# PIC32MZ2048EFM144 register map
Registers are 32-bit, access not given, reset 0x0 unless marked. A register's access mark holds for its fields unless they carry their own. Offsets are from the block's base; [hi:lo] are bit positions; {n}, {i} and the like mark numbered series; 'fields as' and 'values as' point back to an identical list.

## CAN1 — CAN1 peripheral
Base 0xBF880000
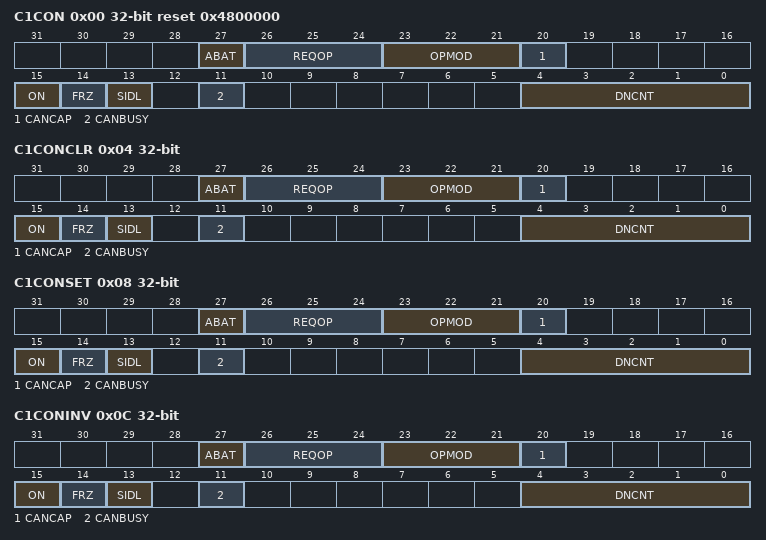
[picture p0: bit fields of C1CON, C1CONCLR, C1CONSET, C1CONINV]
0x00 C1CON reset 0x4800000
  [27] ABAT, [26:24] REQOP, [23:21] OPMOD, [20] CANCAP, [15] ON, [14] FRZ, [13] SIDL, [11] CANBUSY, [4:0] DNCNT
0x04 C1CONCLR
  fields as C1CON
0x08 C1CONSET
  fields as C1CON
0x0C C1CONINV
  fields as C1CON
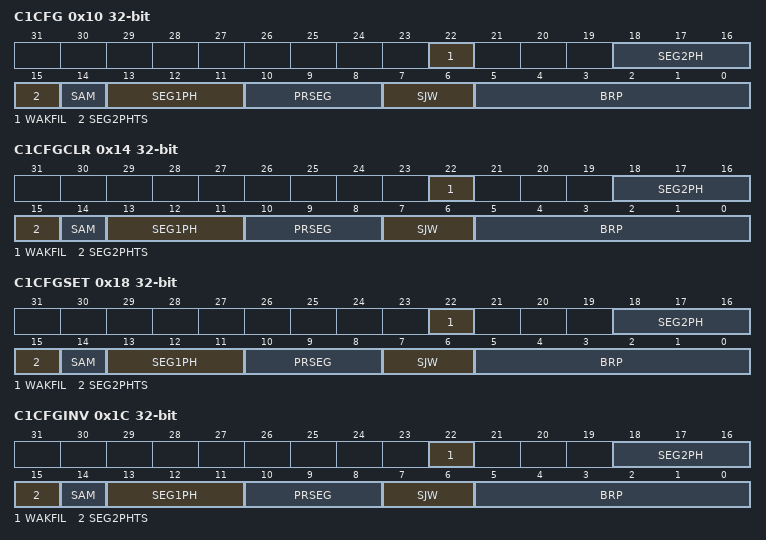
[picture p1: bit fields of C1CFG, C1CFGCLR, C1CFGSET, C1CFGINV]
0x10 C1CFG
  [22] WAKFIL, [18:16] SEG2PH, [15] SEG2PHTS, [14] SAM, [13:11] SEG1PH, [10:8] PRSEG, [7:6] SJW, [5:0] BRP
0x14 C1CFGCLR
  fields as C1CFG
0x18 C1CFGSET
  fields as C1CFG
0x1C C1CFGINV
  fields as C1CFG
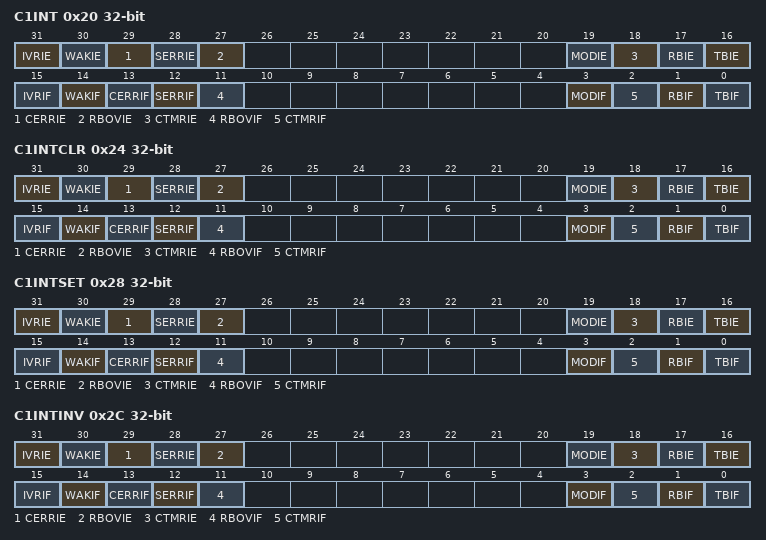
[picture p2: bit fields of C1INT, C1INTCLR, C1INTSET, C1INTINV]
0x20 C1INT
  [31] IVRIE, [30] WAKIE, [29] CERRIE, [28] SERRIE, [27] RBOVIE, [19] MODIE, [18] CTMRIE, [17] RBIE, [16] TBIE, [15] IVRIF, [14] WAKIF, [13] CERRIF, [12] SERRIF, [11] RBOVIF, [3] MODIF, [2] CTMRIF, [1] RBIF, [0] TBIF
0x24 C1INTCLR
  fields as C1INT
0x28 C1INTSET
  fields as C1INT
0x2C C1INTINV
  fields as C1INT
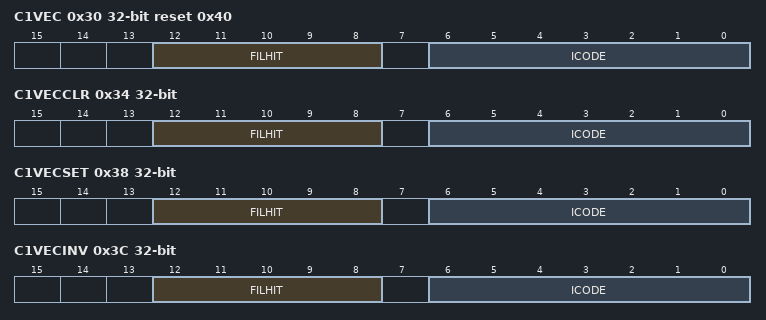
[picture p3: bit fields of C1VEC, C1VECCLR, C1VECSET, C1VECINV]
0x30 C1VEC reset 0x40
  [12:8] FILHIT, [6:0] ICODE
0x34 C1VECCLR
  [12:8] FILHIT, [6:0] ICODE
0x38 C1VECSET
  [12:8] FILHIT, [6:0] ICODE
0x3C C1VECINV
  [12:8] FILHIT, [6:0] ICODE
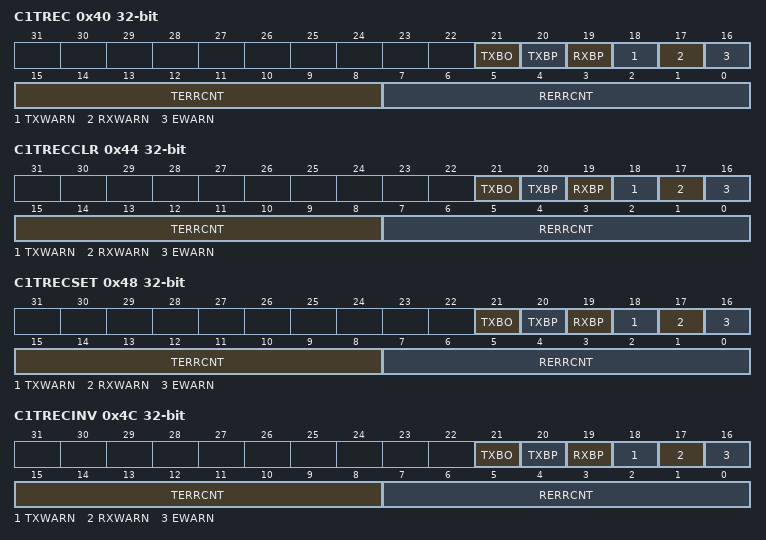
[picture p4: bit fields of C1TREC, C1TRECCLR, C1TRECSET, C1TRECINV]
0x40 C1TREC
  [21] TXBO, [20] TXBP, [19] RXBP, [18] TXWARN, [17] RXWARN, [16] EWARN, [15:8] TERRCNT, [7:0] RERRCNT
0x44 C1TRECCLR
  fields as C1TREC
0x48 C1TRECSET
  fields as C1TREC
0x4C C1TRECINV
  fields as C1TREC
0x50 C1FSTAT
  [31:0] FIFOIP
0x54 C1FSTATCLR
  [31:0] FIFOIP
0x58 C1FSTATSET
  [31:0] FIFOIP
0x5C C1FSTATINV
  [31:0] FIFOIP
0x60 C1RXOVF
  [31:0] RXOVF
0x64 C1RXOVFCLR
  [31:0] RXOVF
0x68 C1RXOVFSET
  [31:0] RXOVF
0x6C C1RXOVFINV
  [31:0] RXOVF
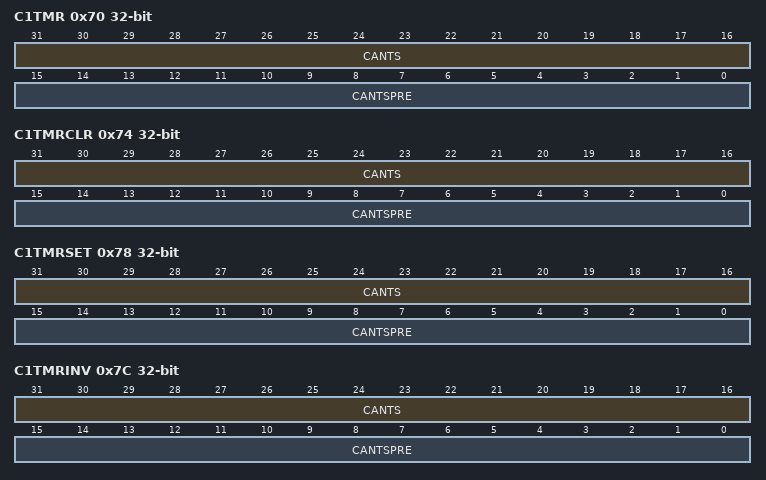
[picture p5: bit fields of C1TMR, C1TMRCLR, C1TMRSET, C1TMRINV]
0x70 C1TMR
  [31:16] CANTS, [15:0] CANTSPRE
0x74 C1TMRCLR
  [31:16] CANTS, [15:0] CANTSPRE
0x78 C1TMRSET
  [31:16] CANTS, [15:0] CANTSPRE
0x7C C1TMRINV
  [31:16] CANTS, [15:0] CANTSPRE
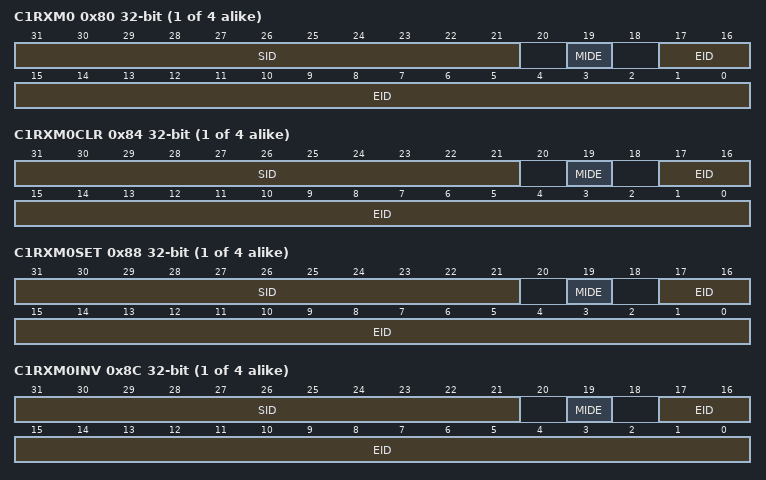
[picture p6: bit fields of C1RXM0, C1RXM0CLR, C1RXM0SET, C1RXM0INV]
{0x80+0x10*i} C1RXM{i} (i=0..3)
  [31:21] SID, [19] MIDE, [17:0] EID
{0x84+0x10*i} C1RXM{i}CLR (i=0..3)
  [31:21] SID, [19] MIDE, [17:0] EID
{0x88+0x10*i} C1RXM{i}SET (i=0..3)
  [31:21] SID, [19] MIDE, [17:0] EID
{0x8C+0x10*i} C1RXM{i}INV (i=0..3)
  [31:21] SID, [19] MIDE, [17:0] EID
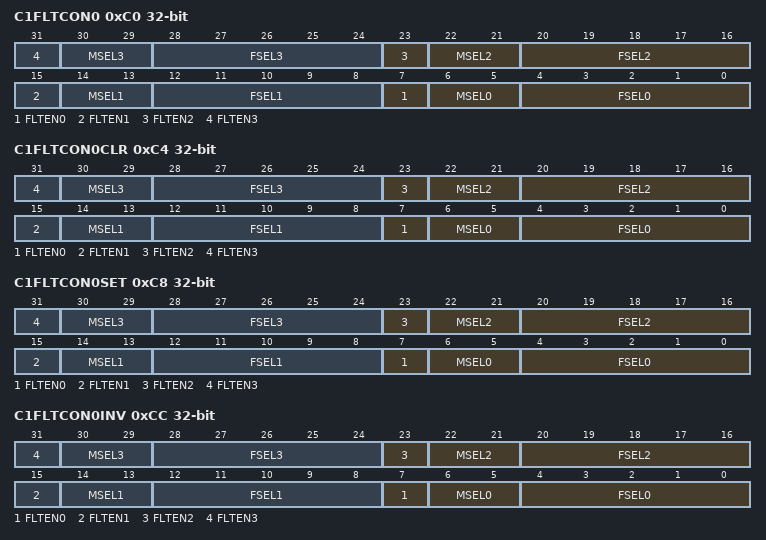
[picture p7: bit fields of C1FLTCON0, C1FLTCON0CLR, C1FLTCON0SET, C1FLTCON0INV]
0xC0 C1FLTCON0
  [8n+7] FLTEN{n} (n=0..3), [8n+6:8n+5] MSEL{n} (n=0..3), [8n+4:8n] FSEL{n} (n=0..3)
0xC4 C1FLTCON0CLR
  fields as C1FLTCON0
0xC8 C1FLTCON0SET
  fields as C1FLTCON0
0xCC C1FLTCON0INV
  fields as C1FLTCON0
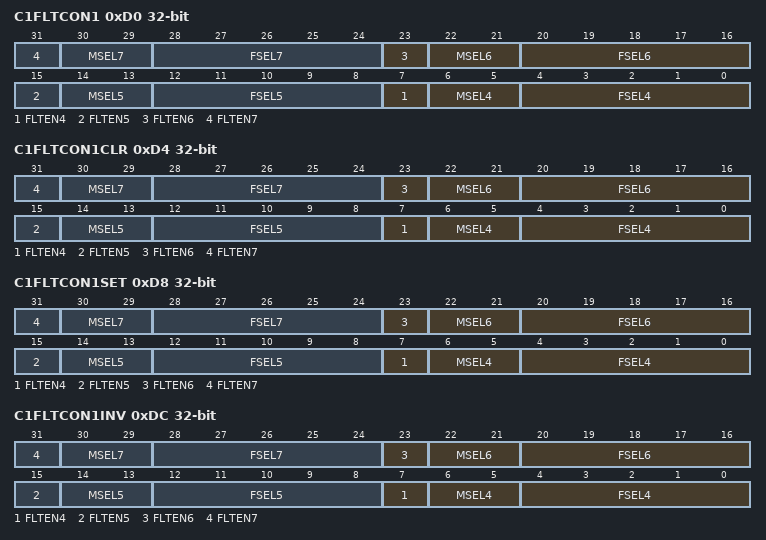
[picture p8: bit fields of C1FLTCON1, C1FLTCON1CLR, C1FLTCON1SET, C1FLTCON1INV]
0xD0 C1FLTCON1
  [8n-25] FLTEN{n} (n=4..7), [8n-26:8n-27] MSEL{n} (n=4..7), [8n-28:8n-32] FSEL{n} (n=4..7)
0xD4 C1FLTCON1CLR
  fields as C1FLTCON1
0xD8 C1FLTCON1SET
  fields as C1FLTCON1
0xDC C1FLTCON1INV
  fields as C1FLTCON1
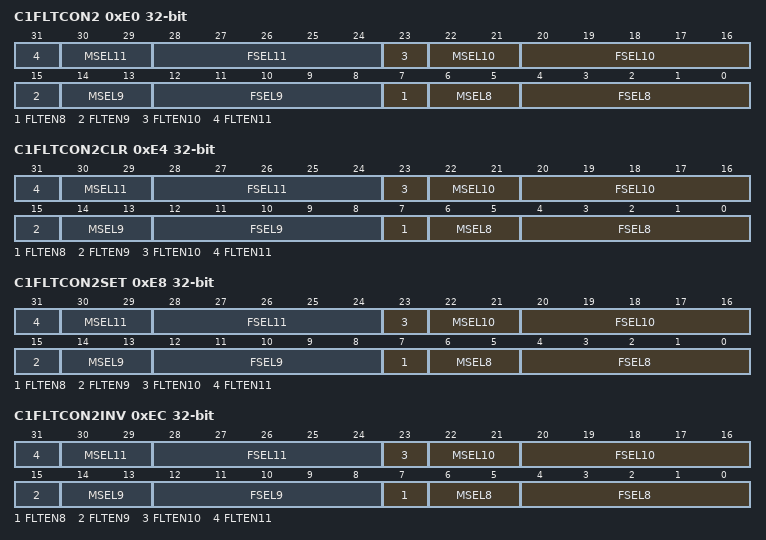
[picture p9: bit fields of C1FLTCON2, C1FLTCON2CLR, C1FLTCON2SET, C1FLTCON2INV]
0xE0 C1FLTCON2
  [8n-57] FLTEN{n} (n=8..11), [8n-58:8n-59] MSEL{n} (n=8..11), [8n-60:8n-64] FSEL{n} (n=8..11)
0xE4 C1FLTCON2CLR
  fields as C1FLTCON2
0xE8 C1FLTCON2SET
  fields as C1FLTCON2
0xEC C1FLTCON2INV
  fields as C1FLTCON2
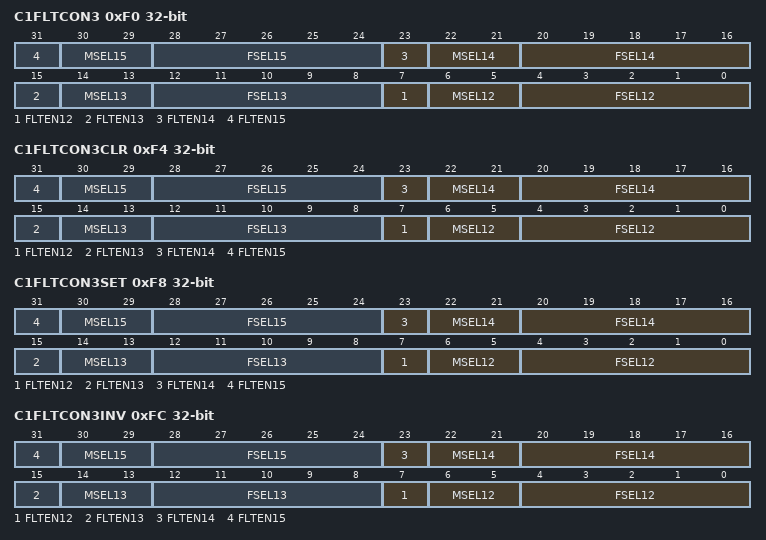
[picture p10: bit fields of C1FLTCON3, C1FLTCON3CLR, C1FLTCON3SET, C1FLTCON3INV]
0xF0 C1FLTCON3
  [8n-89] FLTEN{n} (n=12..15), [8n-90:8n-91] MSEL{n} (n=12..15), [8n-92:8n-96] FSEL{n} (n=12..15)
0xF4 C1FLTCON3CLR
  fields as C1FLTCON3
0xF8 C1FLTCON3SET
  fields as C1FLTCON3
0xFC C1FLTCON3INV
  fields as C1FLTCON3
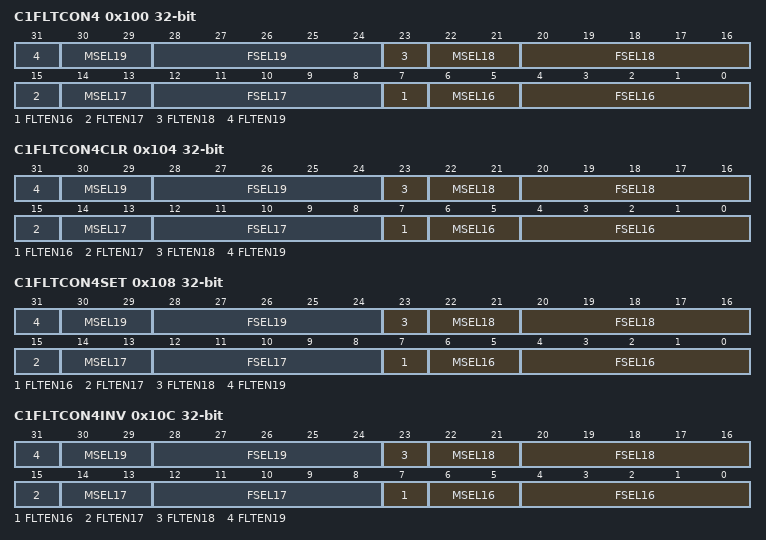
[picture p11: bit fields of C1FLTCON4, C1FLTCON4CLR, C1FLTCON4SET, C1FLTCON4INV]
0x100 C1FLTCON4
  [8n-121] FLTEN{n} (n=16..19), [8n-122:8n-123] MSEL{n} (n=16..19), [8n-124:8n-128] FSEL{n} (n=16..19)
0x104 C1FLTCON4CLR
  fields as C1FLTCON4
0x108 C1FLTCON4SET
  fields as C1FLTCON4
0x10C C1FLTCON4INV
  fields as C1FLTCON4
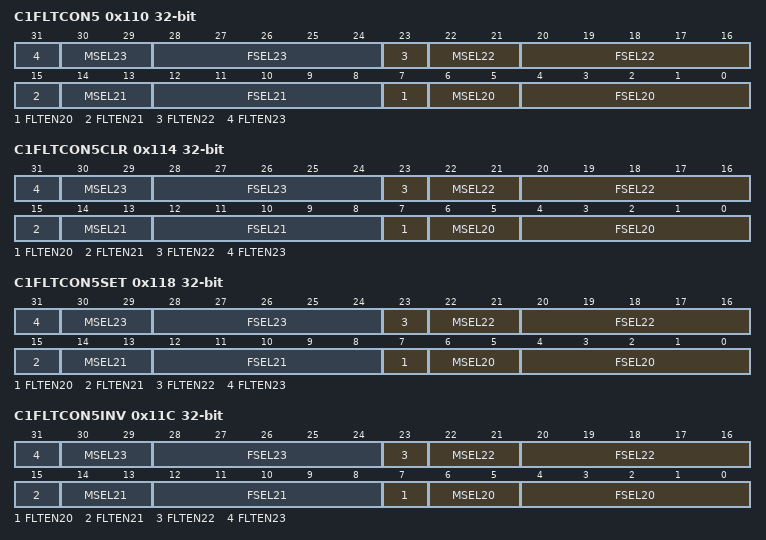
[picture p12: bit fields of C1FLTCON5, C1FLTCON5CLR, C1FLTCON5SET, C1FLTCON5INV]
0x110 C1FLTCON5
  [8n-153] FLTEN{n} (n=20..23), [8n-154:8n-155] MSEL{n} (n=20..23), [8n-156:8n-160] FSEL{n} (n=20..23)
0x114 C1FLTCON5CLR
  fields as C1FLTCON5
0x118 C1FLTCON5SET
  fields as C1FLTCON5
0x11C C1FLTCON5INV
  fields as C1FLTCON5
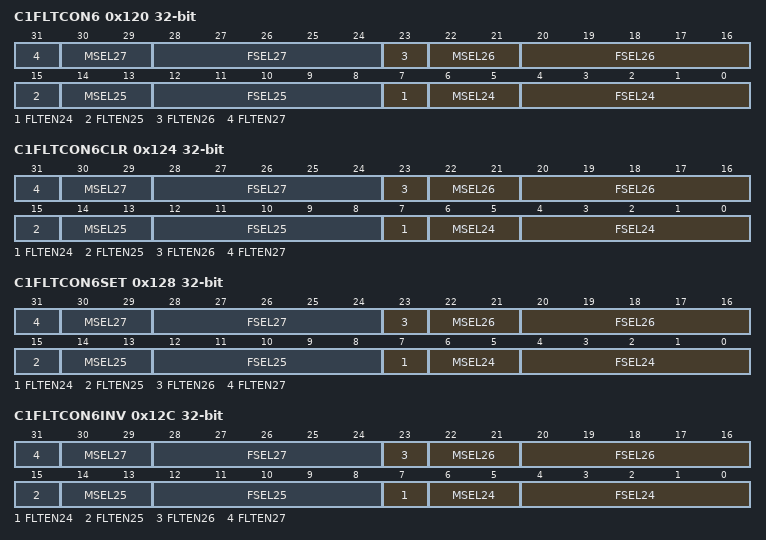
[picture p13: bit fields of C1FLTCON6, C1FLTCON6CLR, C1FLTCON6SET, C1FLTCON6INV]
0x120 C1FLTCON6
  [8n-185] FLTEN{n} (n=24..27), [8n-186:8n-187] MSEL{n} (n=24..27), [8n-188:8n-192] FSEL{n} (n=24..27)
0x124 C1FLTCON6CLR
  fields as C1FLTCON6
0x128 C1FLTCON6SET
  fields as C1FLTCON6
0x12C C1FLTCON6INV
  fields as C1FLTCON6
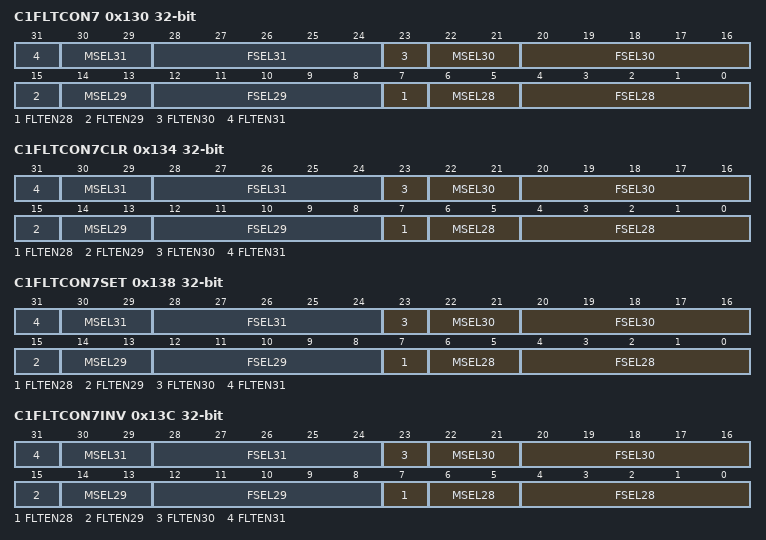
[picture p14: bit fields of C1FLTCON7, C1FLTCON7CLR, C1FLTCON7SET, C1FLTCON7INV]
0x130 C1FLTCON7
  [8n-217] FLTEN{n} (n=28..31), [8n-218:8n-219] MSEL{n} (n=28..31), [8n-220:8n-224] FSEL{n} (n=28..31)
0x134 C1FLTCON7CLR
  fields as C1FLTCON7
0x138 C1FLTCON7SET
  fields as C1FLTCON7
0x13C C1FLTCON7INV
  fields as C1FLTCON7
{0x140+0x10*i} C1RXF{i} (i=0..31)
  [31:21] SID, [19] EXID, [17:0] EID
{0x144+0x10*i} C1RXF{i}CLR (i=0..31)
  [31:21] SID, [19] EXID, [17:0] EID
{0x148+0x10*i} C1RXF{i}SET (i=0..31)
  [31:21] SID, [19] EXID, [17:0] EID
{0x14C+0x10*i} C1RXF{i}INV (i=0..31)
  [31:21] SID, [19] EXID, [17:0] EID
0x340 C1FIFOBA
  [31:2] FIFOBA
0x344 C1FIFOBACLR
  [31:2] FIFOBA
0x348 C1FIFOBASET
  [31:2] FIFOBA
0x34C C1FIFOBAINV
  [31:2] FIFOBA
{0x350+0x40*i} C1FIFOCON{i} (i=0..31)
  [20:16] FSIZE, [14] FRESET, [13] UINC, [12] DONLY, [7] TXEN, [6] TXABAT, [5] TXLARB, [4] TXERR, [3] TXREQ, [2] RTREN, [1:0] TXPRI
{0x354+0x40*i} C1FIFOCON{i}CLR (i=0..31)
  fields as C1FIFOCON0
{0x358+0x40*i} C1FIFOCON{i}SET (i=0..31)
  fields as C1FIFOCON0
{0x35C+0x40*i} C1FIFOCON{i}INV (i=0..31)
  fields as C1FIFOCON0
{0x360+0x40*i} C1FIFOINT{i} (i=0..31)
  [26] TXNFULLIE, [25] TXHALFIE, [24] TXEMPTYIE, [19] RXOVFLIE, [18] RXFULLIE, [17] RXHALFIE, [16] RXNEMPTYIE, [10] TXNFULLIF, [9] TXHALFIF, [8] TXEMPTYIF, [3] RXOVFLIF, [2] RXFULLIF, [1] RXHALFIF, [0] RXNEMPTYIF
{0x364+0x40*i} C1FIFOINT{i}CLR (i=0..31)
  fields as C1FIFOINT0
{0x368+0x40*i} C1FIFOINT{i}SET (i=0..31)
  fields as C1FIFOINT0
{0x36C+0x40*i} C1FIFOINT{i}INV (i=0..31)
  fields as C1FIFOINT0
{0x370+0x40*i} C1FIFOUA{i} (i=0..31)
  [31:2] FIFOUA
{0x374+0x40*i} C1FIFOUA{i}CLR (i=0..31)
  [31:2] FIFOUA
{0x378+0x40*i} C1FIFOUA{i}SET (i=0..31)
  [31:2] FIFOUA
{0x37C+0x40*i} C1FIFOUA{i}INV (i=0..31)
  [31:2] FIFOUA
{0x380+0x40*i} C1FIFOCI{i} (i=0..31)
  [4:0] CFIFOCI
{0x384+0x40*i} C1FIFOCI{i}CLR (i=0..31)
  [4:0] CFIFOCI
{0x388+0x40*i} C1FIFOCI{i}SET (i=0..31)
  [4:0] CFIFOCI
{0x38C+0x40*i} C1FIFOCI{i}INV (i=0..31)
  [4:0] CFIFOCI
